# STM32F413CGU3 register map
File version: 1.0
Registers are 32-bit, access not given, reset 0x0 unless marked. A register's access mark holds for its fields unless they carry their own. Offsets are from the block's base; [hi:lo] are bit positions; {n}, {i} and the like mark numbered series.

## WWDG
Base 0x40002C00
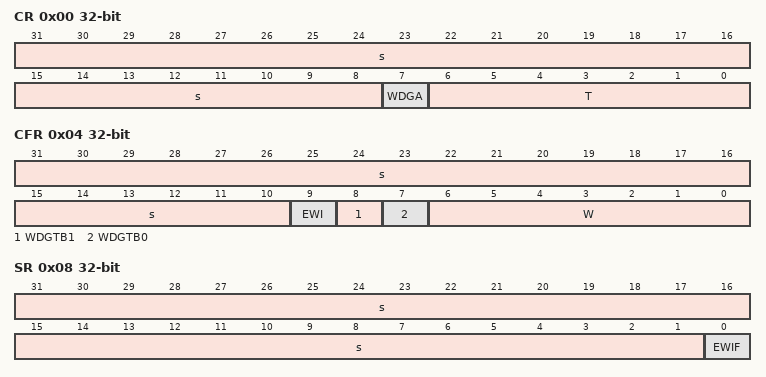
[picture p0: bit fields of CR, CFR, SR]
0x00 CR
  [31:8] s, [7] WDGA, [6:0] T
0x04 CFR
  [31:10] s, [9] EWI, [8] WDGTB1, [7] WDGTB0, [6:0] W
0x08 SR
  [31:1] s, [0] EWIF

## IWDG
Base 0x40003000
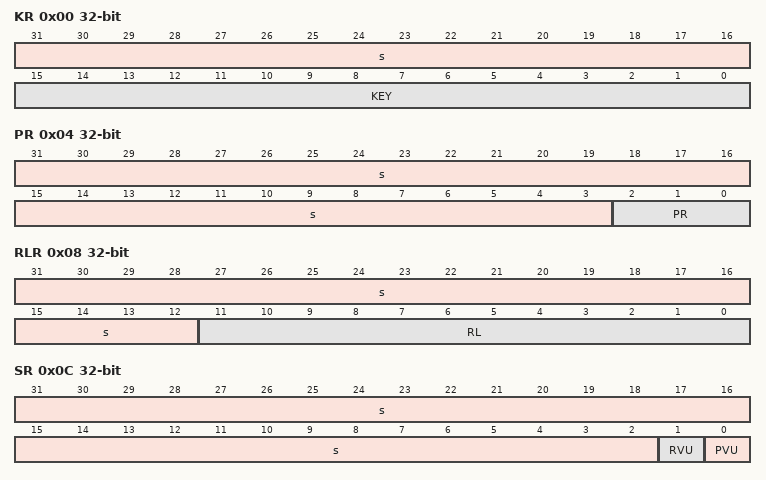
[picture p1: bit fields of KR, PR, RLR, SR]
0x00 KR
  [31:16] s, [15:0] KEY
0x04 PR
  [31:3] s, [2:0] PR
0x08 RLR
  [31:12] s, [11:0] RL
0x0C SR
  [31:2] s, [1] RVU, [0] PVU

## SPI2
Base 0x40003800
Same registers: SPI3 0x40003C00, SPI1 0x40013000, SPI4 0x40013400, SPI5 0x40015000, QSPI 0xA0001000
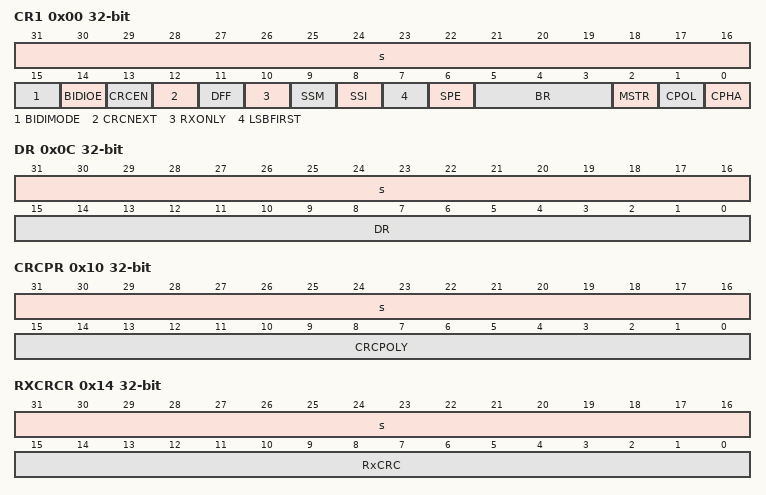
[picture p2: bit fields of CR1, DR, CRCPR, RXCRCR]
0x00 CR1
  [31:16] s, [15] BIDIMODE, [14] BIDIOE, [13] CRCEN, [12] CRCNEXT, [11] DFF, [10] RXONLY, [9] SSM, [8] SSI, [7] LSBFIRST, [6] SPE, [5:3] BR, [2] MSTR, [1] CPOL, [0] CPHA
0x04 CR2
  [7] TXEIE, [6] RXNEIE, [5] ERRIE, [4] FRF, [31:3] s, [2] SSOE, [1] TXDMAEN, [0] RXDMAEN
0x08 SR
0x0C DR
  [31:16] s, [15:0] DR
0x10 CRCPR
  [31:16] s, [15:0] CRCPOLY
0x14 RXCRCR
  [31:16] s, [15:0] RxCRC
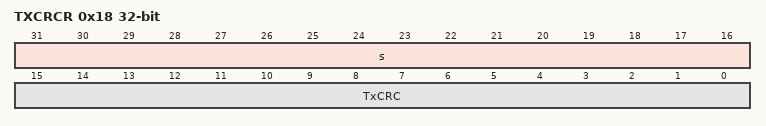
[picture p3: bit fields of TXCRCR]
0x18 TXCRCR
  [31:16] s, [15:0] TxCRC
0x1C I2SCFGR
  [12] ASTREN, [11] I2SMOD, [10] I2SE, [9:8] I2SCFG, [7] PCMSYNC, [31:6] s, [5:4] I2SSTD, [3] CKPOL, [2:1] DATLEN, [0] CHLEN
0x20 I2SPR

## USART2
Base 0x40004400
Same registers: USART3 0x40004800, UART4 0x40004C00, UART5 0x40005000, UART7 0x40007800, UART8 0x40007C00, USART1 0x40011000, USART6 0x40011400, UART9 0x40011800, UART10 0x40011C00
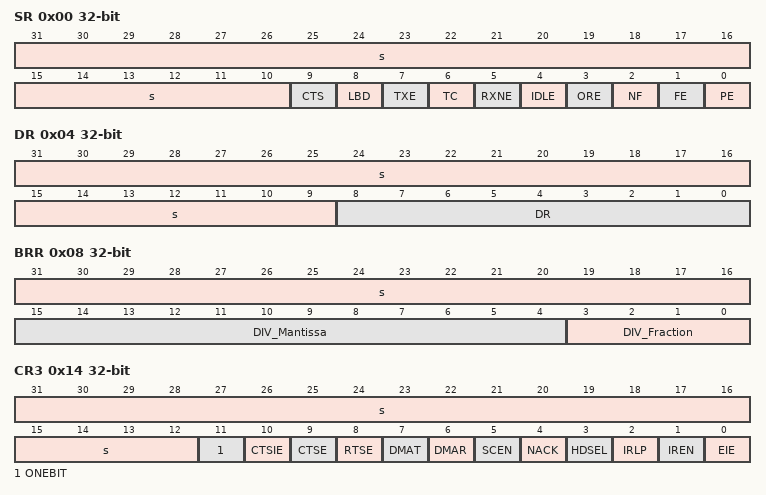
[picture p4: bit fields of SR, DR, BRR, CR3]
0x00 SR
  [31:10] s, [9] CTS, [8] LBD, [7] TXE, [6] TC, [5] RXNE, [4] IDLE, [3] ORE, [2] NF, [1] FE, [0] PE
0x04 DR
  [31:9] s, [8:0] DR
0x08 BRR
  [31:16] s, [15:4] DIV_Mantissa, [3:0] DIV_Fraction
0x0C CR1
  [15] OVER8, [31:14] s, [13] UE, [12] M, [11] WAKE, [10] PCE, [9] PS, [8] PEIE, [7] TXEIE, [6] TCIE, [5] RXNEIE, [4] IDLEIE, [3] TE, [2] RE, [1] RWU, [0] SBK
0x10 CR2
  [14] LINEN, [13:12] STOP, [11] CLKEN, [10] CPOL, [9] CPHA, [8] LBCL, [6] LBDIE, [5] LBDL, [31:4] s, [3:0] ADD
0x14 CR3
  [31:12] s, [11] ONEBIT, [10] CTSIE, [9] CTSE, [8] RTSE, [7] DMAT, [6] DMAR, [5] SCEN, [4] NACK, [3] HDSEL, [2] IRLP, [1] IREN, [0] EIE
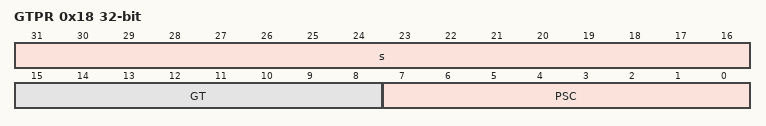
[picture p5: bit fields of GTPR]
0x18 GTPR
  [31:16] s, [15:8] GT, [7:0] PSC

## I2C1
Base 0x40005400
Same registers: I2C2 0x40005800, I2C3 0x40005C00, I2CFMP1 0x40006000
0x00 CR1
  [15] SWRST, [13] ALERT, [12] PEC, [11] POS, [10] ACK, [9] STOP, [8] START, [7] NOSTRETCH, [6] ENGC, [5] ENPEC, [4] ENARP, [3] SMBTYPE, [31:2] s, [1] SMBUS, [0] PE
0x04 CR2
  [12] LAST, [11] DMAEN, [10] ITBUFEN, [9] ITEVTEN, [8] ITERREN, [31:6] s, [5:0] FREQ
0x08 OAR1
  [15] ADDMODE, [31:10] s, [9:1] ADD, [0] ADD0
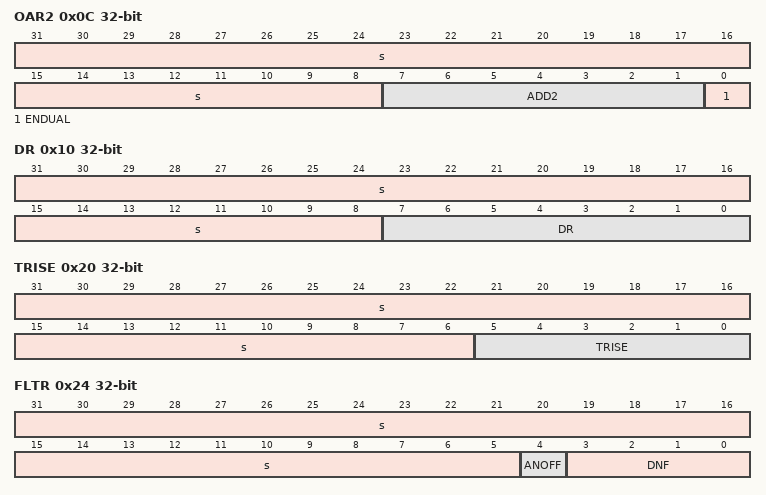
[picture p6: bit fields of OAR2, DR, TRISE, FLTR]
0x0C OAR2
  [31:8] s, [7:1] ADD2, [0] ENDUAL
0x10 DR
  [31:8] s, [7:0] DR
0x14 SR1
  [15] SMBALERT, [14] TIMEOUT, [12] PECERR, [11] OVR, [10] AF, [9] ARLO, [8] BERR, [7] TxE, [6] RxNE, [31:5] s, [4] STOPF, [3] ADD10, [2] BTF, [1] ADDR, [0] SB
0x18 SR2
  [15:8] PEC, [7] DUALF, [6] SMBHOST, [5] SMBDEFAULT, [4] GENCALL, [31:3] s, [2] TRA, [1] BUSY, [0] MSL
0x1C CCR
  [15] F/S, [14] DUTY, [31:12] s, [11:0] CCR
0x20 TRISE
  [31:6] s, [5:0] TRISE
0x24 FLTR
  [31:5] s, [4] ANOFF, [3:0] DNF

## CAN1
Base 0x40006400
Same registers: CAN2 0x40006800, CAN3 0x40006C00
0x00 MCR
  [16] DBF, [15] RESET, [31:8] s, [7] TTCM, [6] ABOM, [5] AWUM, [4] NART, [3] RFLM, [2] TXFP, [1] SLEEP, [0] INRQ
0x04 MSR
  [11] RX, [10] SAMP, [9] RXM, [8] TXM, [31:5] s, [4] SLAKI, [3] WKUI, [2] ERRI, [1] SLAK, [0] INAK
0x08 TSR
  [31:29] LOW, [28:26] TME, [25:24] CODE, [23] ABRQ2, [19] TERR2, [18] ALST2, [17] TXOK2, [16] RQCP2, [15] ABRQ1, [11] TERR1, [10] ALST1, [9] TXOK1, [8] RQCP1, [7] ABRQ0, [22:4] s, [3] TERR0, [2] ALST0, [1] TXOK0, [0] RQCP0
0x0C RF0R
  [5] RFOM0, [4] FOVR0, [3] FULL0, [31:2] s, [1:0] FMP0
0x10 RF1R
  [5] RFOM1, [4] FOVR1, [3] FULL1, [31:2] s, [1:0] FMP1
0x14 IER
  [17] SLKIE, [16] WKUIE, [15] ERRIE, [11] LECIE, [10] BOFIE, [9] EPVIE, [8] EWGIE, [31:7] s, [6] FOVIE1, [5] FFIE1, [4] FMPIE1, [3] FOVIE0, [2] FFIE0, [1] FMPIE0, [0] TMEIE
0x18 ESR
  [31:24] REC, [23:16] TEC, [6:4] LEC, [15:3] s, [2] BOFF, [1] EPVF, [0] EWGF
0x1C BTR
  [31] SILM, [30] LBKM, [25:24] SJW, [22:20] TS2, [19:16] TS1, [29:10] s, [9:0] BRP
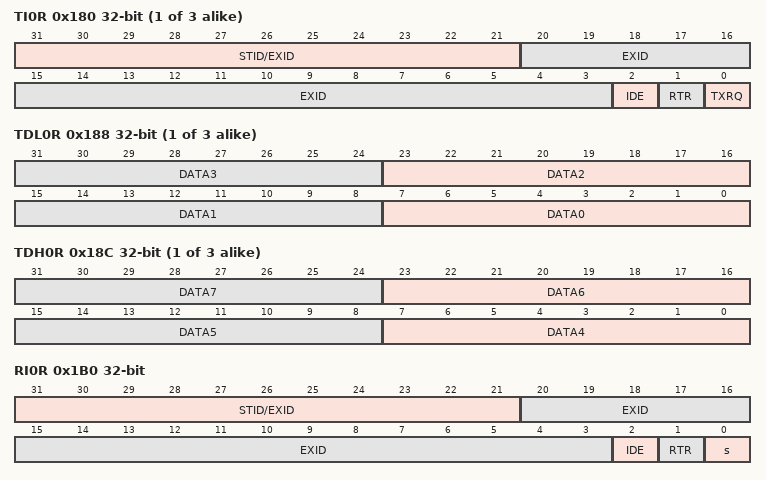
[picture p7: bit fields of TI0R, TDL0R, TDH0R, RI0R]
{0x180+0x10*i} TI{i}R (i=0..2)
  [31:21] STID/EXID, [20:3] EXID, [2] IDE, [1] RTR, [0] TXRQ
{0x184+0x10*i} TDT{i}R (i=0..2)
  [31:16] TIME, [8] TGT, [15:4] s, [3:0] DLC
{0x188+0x10*i} TDL{i}R (i=0..2)
  [8n+7:8n] DATA{n} (n=0..3)
{0x18C+0x10*i} TDH{i}R (i=0..2)
  [8n-25:8n-32] DATA{n} (n=4..7)
0x1B0 RI0R
  [31:21] STID/EXID, [20:3] EXID, [2] IDE, [1] RTR, [0] s
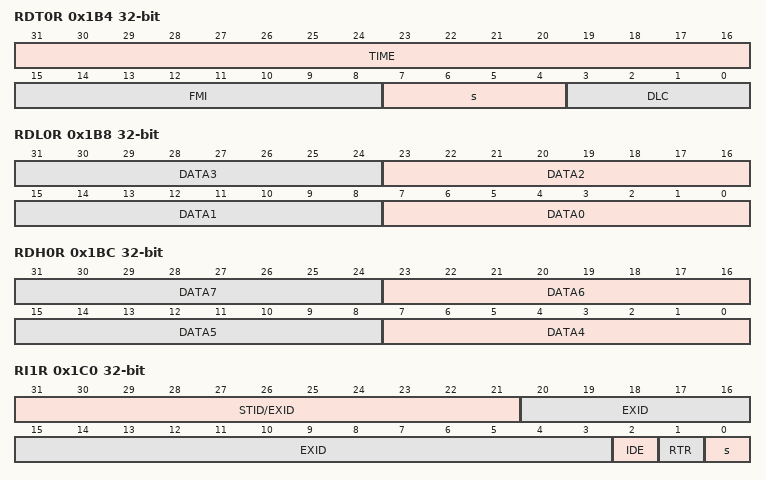
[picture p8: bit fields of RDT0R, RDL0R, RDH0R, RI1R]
0x1B4 RDT0R
  [31:16] TIME, [15:8] FMI, [7:4] s, [3:0] DLC
0x1B8 RDL0R
  [8n+7:8n] DATA{n} (n=0..3)
0x1BC RDH0R
  [8n-25:8n-32] DATA{n} (n=4..7)
0x1C0 RI1R
  [31:21] STID/EXID, [20:3] EXID, [2] IDE, [1] RTR, [0] s
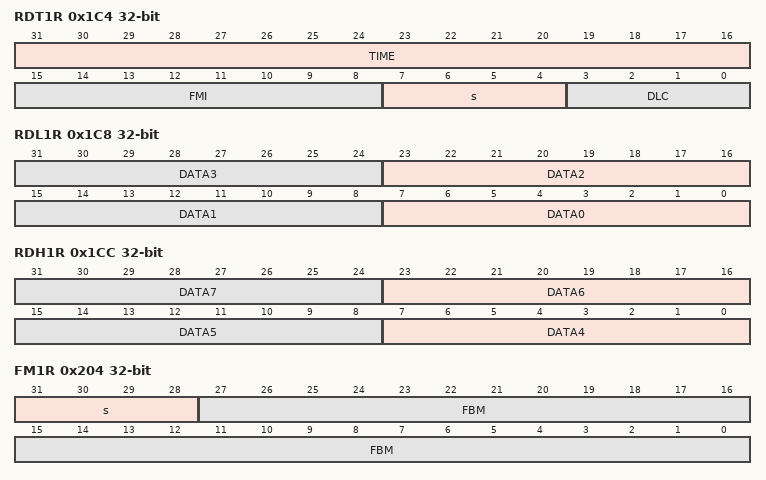
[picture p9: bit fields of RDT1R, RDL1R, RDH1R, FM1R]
0x1C4 RDT1R
  [31:16] TIME, [15:8] FMI, [7:4] s, [3:0] DLC
0x1C8 RDL1R
  [8n+7:8n] DATA{n} (n=0..3)
0x1CC RDH1R
  [8n-25:8n-32] DATA{n} (n=4..7)
0x200 FMR
  [13:8] CANSB, [31:1] s, [0] FINIT
0x204 FM1R
  [31:28] s, [27:0] FBM
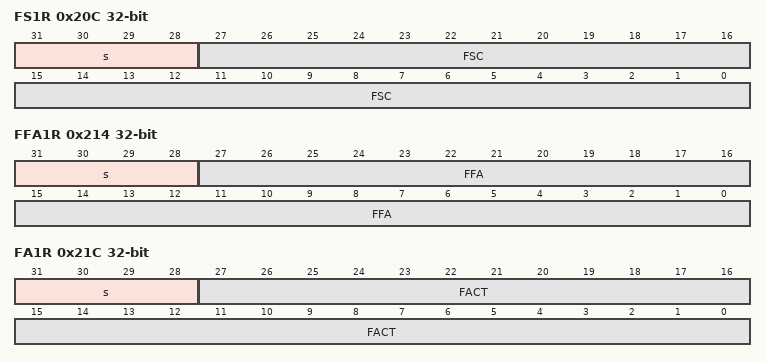
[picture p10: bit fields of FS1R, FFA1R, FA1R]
0x20C FS1R
  [31:28] s, [27:0] FSC
0x214 FFA1R
  [31:28] s, [27:0] FFA
0x21C FA1R
  [31:28] s, [27:0] FACT
0x240 F0R1
  [31:0] FB
0x244 F0R2
  [31:0] FB
0x248 F1R1
  [31:0] FB
0x24C F1R2
  [31:0] FB
0x318 F27R1
  [31:0] FB
0x31C F27R2
  [31:0] FB
